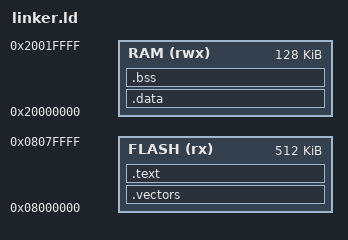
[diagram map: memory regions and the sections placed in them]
ENTRY(_start)

MEMORY
{
    FLASH (rx)  : ORIGIN = 0x08000000, LENGTH = 512K
    RAM   (rwx) : ORIGIN = 0x20000000, LENGTH = 128K
}

_estack = ORIGIN(RAM) + LENGTH(RAM);

SECTIONS
{
    .vectors :
    {
        KEEP(*(.vectors))
    } > FLASH

    .text :
    {
        *(.text*)
        *(.rodata*)
    } > FLASH

    .data : AT (ADDR(.text) + SIZEOF(.text))
    {
        _sdata = .;
        *(.data*)
        _edata = .;
    } > RAM

    .bss :
    {
        _sbss = .;
        *(.bss*)
        *(COMMON)
        _ebss = .;
    } > RAM
}
